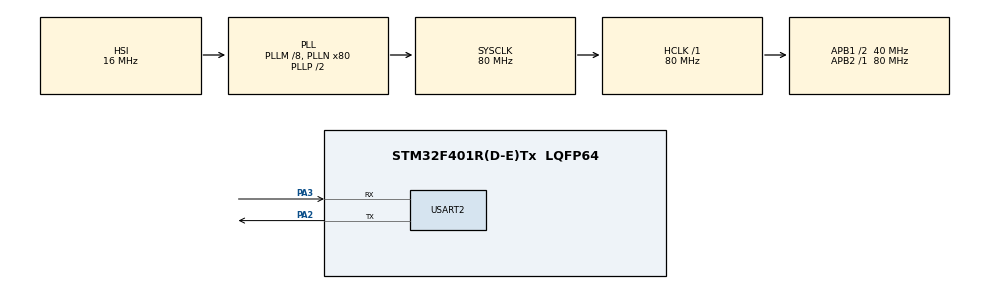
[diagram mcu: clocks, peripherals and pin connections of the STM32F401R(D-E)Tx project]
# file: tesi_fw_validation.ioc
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Dma.Request0=USART2_RX
Dma.Request1=USART2_TX
Dma.USART2_RX.0.Direction=DMA_PERIPH_TO_MEMORY
Dma.USART2_RX.0.FIFOMode=DMA_FIFOMODE_DISABLE
Dma.USART2_RX.0.Instance=DMA1_Stream5
Dma.USART2_RX.0.MemDataAlignment=DMA_MDATAALIGN_BYTE
Dma.USART2_RX.0.MemInc=DMA_MINC_ENABLE
Dma.USART2_RX.0.Mode=DMA_NORMAL
Dma.USART2_RX.0.PeriphDataAlignment=DMA_PDATAALIGN_BYTE
Dma.USART2_RX.0.PeriphInc=DMA_PINC_DISABLE
Dma.USART2_RX.0.Priority=DMA_PRIORITY_LOW
Dma.USART2_TX.1.Direction=DMA_MEMORY_TO_PERIPH
Dma.USART2_TX.1.FIFOMode=DMA_FIFOMODE_DISABLE
Dma.USART2_TX.1.Instance=DMA1_Stream6
Dma.USART2_TX.1.MemDataAlignment=DMA_MDATAALIGN_BYTE
Dma.USART2_TX.1.MemInc=DMA_MINC_ENABLE
Dma.USART2_TX.1.Mode=DMA_NORMAL
Dma.USART2_TX.1.PeriphDataAlignment=DMA_PDATAALIGN_BYTE
Dma.USART2_TX.1.PeriphInc=DMA_PINC_DISABLE
Dma.USART2_TX.1.Priority=DMA_PRIORITY_LOW
Mcu.Family=STM32F4
Mcu.Name=STM32F401R(D-E)Tx
Mcu.Package=LQFP64
NVIC.DMA1_Stream5_IRQn=true\:0\:0\:false\:false\:true\:false\:true\:true
NVIC.DMA1_Stream6_IRQn=true\:0\:0\:false\:false\:true\:false\:true\:true
NVIC.PriorityGroup=NVIC_PRIORITYGROUP_0
NVIC.USART2_IRQn=true\:0\:0\:false\:false\:true\:true\:true\:true
PA2.Mode=Asynchronous
PA2.Signal=USART2_TX
PA3.Mode=Asynchronous
PA3.Signal=USART2_RX
ProjectManager.HeapSize=0x200
ProjectManager.StackSize=0x400
ProjectManager.TargetToolchain=STM32CubeIDE
RCC.48MHZClocksFreq_Value=22857142.85714286
RCC.AHBFreq_Value=80000000
RCC.APB1CLKDivider=RCC_HCLK_DIV2
RCC.APB1Freq_Value=40000000
RCC.APB1TimFreq_Value=80000000
RCC.APB2Freq_Value=80000000
RCC.APB2TimFreq_Value=80000000
RCC.CortexFreq_Value=80000000
RCC.HCLKFreq_Value=80000000
RCC.HSE_VALUE=8000000
RCC.HSI_VALUE=16000000
RCC.LSE_VALUE=32768
RCC.PLLM=8
RCC.PLLN=80
RCC.PLLQ=7
RCC.SYSCLKFreq_VALUE=80000000
RCC.SYSCLKSource=RCC_SYSCLKSOURCE_PLLCLK
RCC.VCOOutputFreq_Value=160000000
USART2.VirtualMode=VM_ASYNC
board=NUCLEO-F401RE

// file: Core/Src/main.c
/* USER CODE BEGIN Header */
/**
  ******************************************************************************
  * @file           : main.c
  * @brief          : Main program body
  ******************************************************************************
  * @attention
  *
  * Copyright (c) 2024 STMicroelectronics.
  * All rights reserved.
  *
  * This software is licensed under terms that can be found in the LICENSE file
  * in the root directory of this software component.
  * If no LICENSE file comes with this software, it is provided AS-IS.
  *
  ******************************************************************************
  */
/* USER CODE END Header */
#include "main.h"
#include "dma.h"
#include "usart.h"
#include "gpio.h"

/* USER CODE BEGIN Includes */
#include "dsp/filtering_functions.h"
#include "dsp/basic_math_functions.h"

#include "filter_coefs.h"
#include "model_coefs.h"
#include "signal_utils.h"
/* USER CODE END Includes */

/* USER CODE BEGIN PV */
mch_state state = MCH_STATE_WAIT_NWIN;

uint32_t uart_rxbuf[CFG_CHUNKLEN];
uint8_t uart_txbuf[4]; // window number and predicted value

float sigbuf[CFG_SIGLEN];
float signorm[CFG_SIGLEN];

uint32_t chunk_count = 0;
uint32_t curr_nwin = 0;
float curr_pred = 0;

arm_fir_instance_f32 fir;
float fir_state[CFG_SIGLEN+FILT_FIR_NTAPS-1];

sig_fiducials fid;
float features[66];
float tmp[1000];
/* USER CODE END PV */

void SystemClock_Config(void);

int main(void)
{

  /* MCU Configuration--------------------------------------------------------*/

  /* Reset of all peripherals, Initializes the Flash interface and the Systick. */
  HAL_Init();

  /* Configure the system clock */
  SystemClock_Config();

  /* Initialize all configured peripherals */
  MX_GPIO_Init();
  MX_DMA_Init();
  MX_USART2_UART_Init();
  /* USER CODE BEGIN 2 */
  arm_fir_init_f32(&fir, FILT_FIR_NTAPS, FILT_FIR_COEFS, fir_state, CFG_SIGLEN);
  HAL_UART_Receive_DMA(&huart2, (uint8_t*)uart_rxbuf, 1*sizeof(uint32_t));
  /* USER CODE END 2 */

  /* Infinite loop */
  while (1)
  {

  }
}

void SystemClock_Config(void)
{
  RCC_OscInitTypeDef RCC_OscInitStruct = {0};
  RCC_ClkInitTypeDef RCC_ClkInitStruct = {0};

  /** Configure the main internal regulator output voltage
  */
  __HAL_RCC_PWR_CLK_ENABLE();
  __HAL_PWR_VOLTAGESCALING_CONFIG(PWR_REGULATOR_VOLTAGE_SCALE2);

  /** Initializes the RCC Oscillators according to the specified parameters
  * in the RCC_OscInitTypeDef structure.
  */
  RCC_OscInitStruct.OscillatorType = RCC_OSCILLATORTYPE_HSI;
  RCC_OscInitStruct.HSIState = RCC_HSI_ON;
  RCC_OscInitStruct.HSICalibrationValue = RCC_HSICALIBRATION_DEFAULT;
  RCC_OscInitStruct.PLL.PLLState = RCC_PLL_ON;
  RCC_OscInitStruct.PLL.PLLSource = RCC_PLLSOURCE_HSI;
  RCC_OscInitStruct.PLL.PLLM = 8;
  RCC_OscInitStruct.PLL.PLLN = 80;
  RCC_OscInitStruct.PLL.PLLP = RCC_PLLP_DIV2;
  RCC_OscInitStruct.PLL.PLLQ = 7;
  if (HAL_RCC_OscConfig(&RCC_OscInitStruct) != HAL_OK)
  {
    Error_Handler();
  }

  /** Initializes the CPU, AHB and APB buses clocks
  */
  RCC_ClkInitStruct.ClockType = RCC_CLOCKTYPE_HCLK|RCC_CLOCKTYPE_SYSCLK
                              |RCC_CLOCKTYPE_PCLK1|RCC_CLOCKTYPE_PCLK2;
  RCC_ClkInitStruct.SYSCLKSource = RCC_SYSCLKSOURCE_PLLCLK;
  RCC_ClkInitStruct.AHBCLKDivider = RCC_SYSCLK_DIV1;
  RCC_ClkInitStruct.APB1CLKDivider = RCC_HCLK_DIV2;
  RCC_ClkInitStruct.APB2CLKDivider = RCC_HCLK_DIV1;

  if (HAL_RCC_ClockConfig(&RCC_ClkInitStruct, FLASH_LATENCY_2) != HAL_OK)
  {
    Error_Handler();
  }
}

/* USER CODE BEGIN 4 */
void HAL_UART_TxCpltCallback(UART_HandleTypeDef *huart) {
}

void HAL_UART_RxCpltCallback(UART_HandleTypeDef *huart) {
	if (huart->Instance == USART2) {

		if (state == MCH_STATE_WAIT_NWIN) {
			curr_nwin += 1;
			uart_txbuf[0] = 0x06;
			HAL_UART_Transmit_DMA(&huart2, uart_txbuf, 4);
			state = MCH_STATE_WAIT_DEMOG;
			// 5 demographic features
			HAL_UART_Receive_DMA(&huart2, (uint8_t*)features, 5*sizeof(float));
		}

		else if (state == MCH_STATE_WAIT_DEMOG) {
			state = MCH_STATE_WAIT_DATA;
			HAL_UART_Receive_DMA(&huart2, (uint8_t*)uart_rxbuf, CFG_CHUNKLEN*sizeof(uint32_t));

		}

		else if(state == MCH_STATE_WAIT_DATA) {
			if (chunk_count >= CFG_WINSIZE - 1) {
				state = MCH_STATE_VALIDAT;

				arm_fir_f32(&fir, sigbuf, sigbuf, CFG_SIGLEN);
				sig_norm(sigbuf, CFG_SIGLEN, signorm, SIG_NORM_RANGE);
				sig_get_fiducials(signorm, CFG_SIGLEN, &fid);

				curr_pred = 0;
				if (fid.n_speaks >= 2 && fid.n_valleys >= 2 && fid.n_dpeaks >= 1) {
					// start filling features from position 5 (after demographic features)
					sig_featex(sigbuf, CFG_SIGLEN, fid, tmp, features+5);

					arm_sub_f32(features, SVM_DBP_SMIN, features, 66);
					for (size_t i = 0; i < 66; i++) {
						features[i] /= SVM_DBP_SDIF[i];
					}

					arm_dot_prod_f32(features, SVM_DBP_BETA, 66, &curr_pred);
					curr_pred += SVM_DBP_BIAS;
				}

				memcpy(uart_txbuf, &curr_pred, 4);
				HAL_UART_Transmit_DMA(&huart2, uart_txbuf, 4);
				chunk_count = 0;
				state = MCH_STATE_WAIT_NWIN;
				HAL_UART_Receive_DMA(&huart2, (uint8_t*)uart_rxbuf, 1*sizeof(uint32_t));
			}
			else {
				float* bufcell = sigbuf+chunk_count*CFG_CHUNKLEN;
				memcpy(bufcell, uart_rxbuf, CFG_CHUNKLEN*sizeof(uint32_t));
				chunk_count += 1;
				HAL_UART_Receive_DMA(&huart2, (uint8_t*)uart_rxbuf, CFG_CHUNKLEN*sizeof(float));
			}
		}
	}
}
/* USER CODE END 4 */

void Error_Handler(void)
{
  __disable_irq();
  while (1)
  {
  }
}
